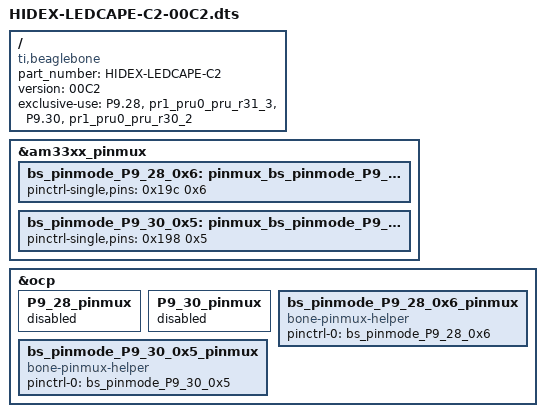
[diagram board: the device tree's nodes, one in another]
/*
 * This is a template-generated file from BoneScript
 */

/dts-v1/;
/plugin/;

/{
    compatible = "ti,beaglebone", "ti,beaglebone-black";
    part_number = "HIDEX-LEDCAPE-C2";
    version = "00C2";

    exclusive-use =
        "P9.28",
        "pr1_pru0_pru_r31_3",
        "P9.30",
        "pr1_pru0_pru_r30_2";

    fragment@0 {
        target = <&am33xx_pinmux>;
        __overlay__ {
            bs_pinmode_P9_28_0x6: pinmux_bs_pinmode_P9_28_0x6 {
                pinctrl-single,pins = <0x19c 0x6>;
            };

            bs_pinmode_P9_30_0x5: pinmux_bs_pinmode_P9_30_0x5 {
                pinctrl-single,pins = <0x198 0x5>;
            };
        };
    };

    fragment@1 {
        target = <&ocp>;
        __overlay__ {
            /*
             * Free up the pins used by the cape from the pinmux helpers.
             */
            P9_28_pinmux { status = "disabled"; };  /* P9_28: pr1_pru0_pru_r31_3 */
            P9_30_pinmux { status = "disabled"; };  /* P9_30: pr1_pru0_pru_r30_2 */

            bs_pinmode_P9_28_0x6_pinmux {
                compatible = "bone-pinmux-helper";
                status = "okay";
                pinctrl-names = "default";
                pinctrl-0 = <&bs_pinmode_P9_28_0x6>;
            };

            bs_pinmode_P9_30_0x5_pinmux {
                compatible = "bone-pinmux-helper";
                status = "okay";
                pinctrl-names = "default";
                pinctrl-0 = <&bs_pinmode_P9_30_0x5>;
            };
        };
    };
};
